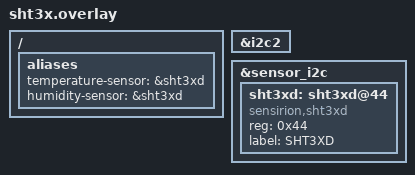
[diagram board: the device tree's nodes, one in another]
/*
 * Copyright (c) 2022 Achim Kraus CloudCoap.net
 *
 * See the NOTICE file(s) distributed with this work for additional
 * information regarding copyright ownership.
 *
 * This program and the accompanying materials are made available under the
 * terms of the Eclipse Public License 2.0 which is available at
 * http://www.eclipse.org/legal/epl-2.0
 *
 * SPDX-License-Identifier: EPL-2.0
 */

/*
 * Usage: 
 *
 * west build -d build_nrf9160dk_nrf9160_ns -b nrf9160dk_nrf9160_ns --pristine -- \
 *    -DOVERLAY_CONFIG="sht3x-prj.conf" -DDTC_OVERLAY_FILE="boards/nrf9160dk_nrf9160_ns.overlay;sht3x.overlay" 
 */ 

/ {
	/* Map the devices to the aliases of the application. */ 
	aliases {	

		/* alias for sensor with SENSOR_CHAN_AMBIENT_TEMP channel */
		temperature-sensor = &sht3xd;
		/* alias for sensor with SENSOR_CHAN_HUMIDITY channel */
		humidity-sensor = &sht3xd;
	};
	
};

&i2c2 {
    /* delete BME680 from Thingy:91 device tree */
	/delete-node/ bme680@76;
};

&sensor_i2c {

	sht3xd: sht3xd@44 { /* ALERT P1.10 */
		compatible = "sensirion,sht3xd";
		reg = <0x44>;
		label = "SHT3XD";
	};
};
